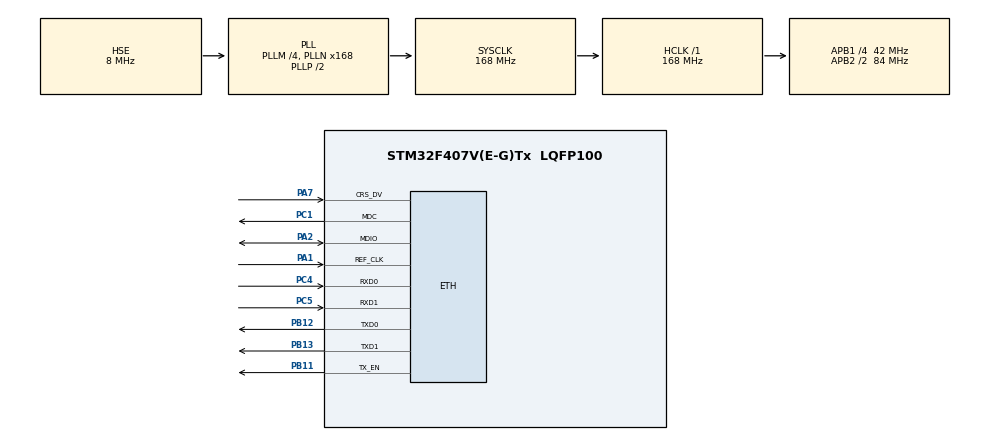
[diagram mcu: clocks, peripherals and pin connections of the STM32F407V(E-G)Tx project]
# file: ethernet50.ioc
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ETH.MACAddr=44\:13\:E8\:26\:51\:B7
ETH.MediaInterface=ETH_MEDIA_INTERFACE_RMII
ETH.PHY_Name_RMII=LAN8742A_PHY_ADDRESS
ETH.PhyAddress=1
LWIP.GATEWAY_ADDRESS=192.168.001.254
LWIP.IP_ADDRESS=192.168.001.101
LWIP.LWIP_DHCP=0
LWIP.LWIP_HTTPD=1
LWIP.LWIP_HTTPD_SSI=1
LWIP.MEMP_NUM_TCP_SEG=24
LWIP.MEM_SIZE=2048
LWIP.NETMASK_ADDRESS=255.255.255.000
LWIP.TCP_MSS=480
LWIP.TCP_SND_BUF=1840
LWIP.TCP_WND=2048
LWIP.Version=v2.0.3_Cube
Mcu.Family=STM32F4
Mcu.Name=STM32F407V(E-G)Tx
Mcu.Package=LQFP100
NVIC.ETH_IRQn=true\:0\:0\:false\:false\:true\:true
NVIC.PriorityGroup=NVIC_PRIORITYGROUP_4
PA1.GPIO_PuPd=GPIO_PULLUP
PA1.GPIO_Speed=GPIO_SPEED_FREQ_VERY_HIGH
PA1.Mode=RMII
PA1.Signal=ETH_REF_CLK
PA13.Mode=Serial_Wire
PA13.Signal=SYS_JTMS-SWDIO
PA14.Mode=Serial_Wire
PA14.Signal=SYS_JTCK-SWCLK
PA2.GPIO_PuPd=GPIO_PULLUP
PA2.GPIO_Speed=GPIO_SPEED_FREQ_VERY_HIGH
PA2.Mode=RMII
PA2.Signal=ETH_MDIO
PA7.GPIO_PuPd=GPIO_PULLUP
PA7.GPIO_Speed=GPIO_SPEED_FREQ_VERY_HIGH
PA7.Mode=RMII
PA7.Signal=ETH_CRS_DV
PB11.GPIO_PuPd=GPIO_PULLUP
PB11.GPIO_Speed=GPIO_SPEED_FREQ_VERY_HIGH
PB11.Mode=RMII
PB11.Signal=ETH_TX_EN
PB12.GPIO_PuPd=GPIO_PULLUP
PB12.GPIO_Speed=GPIO_SPEED_FREQ_VERY_HIGH
PB12.Mode=RMII
PB12.Signal=ETH_TXD0
PB13.GPIO_PuPd=GPIO_PULLUP
PB13.GPIO_Speed=GPIO_SPEED_FREQ_VERY_HIGH
PB13.Mode=RMII
PB13.Signal=ETH_TXD1
PC1.GPIO_PuPd=GPIO_PULLUP
PC1.GPIO_Speed=GPIO_SPEED_FREQ_VERY_HIGH
PC1.Mode=RMII
PC1.Signal=ETH_MDC
PC4.GPIO_PuPd=GPIO_PULLUP
PC4.GPIO_Speed=GPIO_SPEED_FREQ_VERY_HIGH
PC4.Mode=RMII
PC4.Signal=ETH_RXD0
PC5.GPIO_PuPd=GPIO_PULLUP
PC5.GPIO_Speed=GPIO_SPEED_FREQ_VERY_HIGH
PC5.Mode=RMII
PC5.Signal=ETH_RXD1
PH0-OSC_IN.Mode=HSE-External-Oscillator
PH0-OSC_IN.Signal=RCC_OSC_IN
PH1-OSC_OUT.Mode=HSE-External-Oscillator
PH1-OSC_OUT.Signal=RCC_OSC_OUT
ProjectManager.HeapSize=0x2000
ProjectManager.StackSize=0x4000
ProjectManager.TargetToolchain=Makefile
RCC.48MHZClocksFreq_Value=84000000
RCC.AHBFreq_Value=168000000
RCC.APB1CLKDivider=RCC_HCLK_DIV4
RCC.APB1Freq_Value=42000000
RCC.APB1TimFreq_Value=84000000
RCC.APB2CLKDivider=RCC_HCLK_DIV2
RCC.APB2Freq_Value=84000000
RCC.APB2TimFreq_Value=168000000
RCC.CortexFreq_Value=168000000
RCC.EnbaleCSS=true
RCC.HCLKFreq_Value=168000000
RCC.HSE_VALUE=8000000
RCC.HSI_VALUE=16000000
RCC.LSE_VALUE=32768
RCC.PLLM=4
RCC.PLLN=168
RCC.PLLSourceVirtual=RCC_PLLSOURCE_HSE
RCC.SYSCLKFreq_VALUE=168000000
RCC.SYSCLKSource=RCC_SYSCLKSOURCE_PLLCLK
RCC.VCOOutputFreq_Value=336000000
VP_LWIP_VS_Enabled.Mode=Enabled
board=custom

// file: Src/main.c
/* USER CODE BEGIN Header */
/**
  ******************************************************************************
  * @file           : main.c
  * @brief          : Main program body
  ******************************************************************************
  * This notice applies to any and all portions of this file
  * that are not between comment pairs USER CODE BEGIN and
  * USER CODE END. Other portions of this file, whether
  * inserted by the user or by software development tools
  * are owned by their respective copyright owners.
  *
  * Copyright (c) 2024 STMicroelectronics International N.V.
  * All rights reserved.
  *
  * Redistribution and use in source and binary forms, with or without
  * modification, are permitted, provided that the following conditions are met:
  *
  * 1. Redistribution of source code must retain the above copyright notice,
  *    this list of conditions and the following disclaimer.
  * 2. Redistributions in binary form must reproduce the above copyright notice,
  *    this list of conditions and the following disclaimer in the documentation
  *    and/or other materials provided with the distribution.
  * 3. Neither the name of STMicroelectronics nor the names of other
  *    contributors to this software may be used to endorse or promote products
  *    derived from this software without specific written permission.
  * 4. This software, including modifications and/or derivative works of this
  *    software, must execute solely and exclusively on microcontroller or
  *    microprocessor devices manufactured by or for STMicroelectronics.
  * 5. Redistribution and use of this software other than as permitted under
  *    this license is void and will automatically terminate your rights under
  *    this license.
  *
  * THIS SOFTWARE IS PROVIDED BY STMICROELECTRONICS AND CONTRIBUTORS "AS IS"
  * AND ANY EXPRESS, IMPLIED OR STATUTORY WARRANTIES, INCLUDING, BUT NOT
  * LIMITED TO, THE IMPLIED WARRANTIES OF MERCHANTABILITY, FITNESS FOR A
  * PARTICULAR PURPOSE AND NON-INFRINGEMENT OF THIRD PARTY INTELLECTUAL PROPERTY
  * RIGHTS ARE DISCLAIMED TO THE FULLEST EXTENT PERMITTED BY LAW. IN NO EVENT
  * SHALL STMICROELECTRONICS OR CONTRIBUTORS BE LIABLE FOR ANY DIRECT, INDIRECT,
  * INCIDENTAL, SPECIAL, EXEMPLARY, OR CONSEQUENTIAL DAMAGES (INCLUDING, BUT NOT
  * LIMITED TO, PROCUREMENT OF SUBSTITUTE GOODS OR SERVICES; LOSS OF USE, DATA,
  * OR PROFITS; OR BUSINESS INTERRUPTION) HOWEVER CAUSED AND ON ANY THEORY OF
  * LIABILITY, WHETHER IN CONTRACT, STRICT LIABILITY, OR TORT (INCLUDING
  * NEGLIGENCE OR OTHERWISE) ARISING IN ANY WAY OUT OF THE USE OF THIS SOFTWARE,
  * EVEN IF ADVISED OF THE POSSIBILITY OF SUCH DAMAGE.
  *
  ******************************************************************************
  */
/* USER CODE END Header */

#include "main.h"
#include "lwip.h"

/* USER CODE BEGIN Includes */
#include "udpRAW.h"
#include "tcpRAW.h"
#include "http_ssi.h"
/* USER CODE END Includes */

void SystemClock_Config(void);
static void MX_GPIO_Init(void);

/* USER CODE BEGIN 0 */
extern struct netif gnetif;
/* USER CODE END 0 */

int main(void)
{

  /* MCU Configuration--------------------------------------------------------*/

  /* Reset of all peripherals, Initializes the Flash interface and the Systick. */
  HAL_Init();

  /* Configure the system clock */
  SystemClock_Config();

  /* Initialize all configured peripherals */
  MX_GPIO_Init();
  MX_LWIP_Init();
  /* USER CODE BEGIN 2 */
  http_server_init();
  // tcp_client_init();
  //udpServer_init();
  /* USER CODE END 2 */

  /* Infinite loop */
  while (1)
  {

    /* USER CODE BEGIN 3 */
    ethernetif_input(&gnetif);
    sys_check_timeouts();
  }
  /* USER CODE END 3 */
}

void SystemClock_Config(void)
{
  RCC_OscInitTypeDef RCC_OscInitStruct = {0};
  RCC_ClkInitTypeDef RCC_ClkInitStruct = {0};

  /**Configure the main internal regulator output voltage
  */
  __HAL_RCC_PWR_CLK_ENABLE();
  __HAL_PWR_VOLTAGESCALING_CONFIG(PWR_REGULATOR_VOLTAGE_SCALE1);
  /**Initializes the CPU, AHB and APB busses clocks
  */
  RCC_OscInitStruct.OscillatorType = RCC_OSCILLATORTYPE_HSE;
  RCC_OscInitStruct.HSEState = RCC_HSE_ON;
  RCC_OscInitStruct.PLL.PLLState = RCC_PLL_ON;
  RCC_OscInitStruct.PLL.PLLSource = RCC_PLLSOURCE_HSE;
  RCC_OscInitStruct.PLL.PLLM = 4;
  RCC_OscInitStruct.PLL.PLLN = 168;
  RCC_OscInitStruct.PLL.PLLP = RCC_PLLP_DIV2;
  RCC_OscInitStruct.PLL.PLLQ = 4;
  if (HAL_RCC_OscConfig(&RCC_OscInitStruct) != HAL_OK)
  {
    Error_Handler();
  }
  /**Initializes the CPU, AHB and APB busses clocks
  */
  RCC_ClkInitStruct.ClockType = RCC_CLOCKTYPE_HCLK|RCC_CLOCKTYPE_SYSCLK
                              |RCC_CLOCKTYPE_PCLK1|RCC_CLOCKTYPE_PCLK2;
  RCC_ClkInitStruct.SYSCLKSource = RCC_SYSCLKSOURCE_PLLCLK;
  RCC_ClkInitStruct.AHBCLKDivider = RCC_SYSCLK_DIV1;
  RCC_ClkInitStruct.APB1CLKDivider = RCC_HCLK_DIV4;
  RCC_ClkInitStruct.APB2CLKDivider = RCC_HCLK_DIV2;

  if (HAL_RCC_ClockConfig(&RCC_ClkInitStruct, FLASH_LATENCY_5) != HAL_OK)
  {
    Error_Handler();
  }
  /**Enables the Clock Security System
  */
  HAL_RCC_EnableCSS();
}

static void MX_GPIO_Init(void)
{

  /* GPIO Ports Clock Enable */
  __HAL_RCC_GPIOH_CLK_ENABLE();
  __HAL_RCC_GPIOC_CLK_ENABLE();
  __HAL_RCC_GPIOA_CLK_ENABLE();
  __HAL_RCC_GPIOB_CLK_ENABLE();

}

void Error_Handler(void)
{
}

/************************ (C) COPYRIGHT STMicroelectronics *****END OF FILE****/
